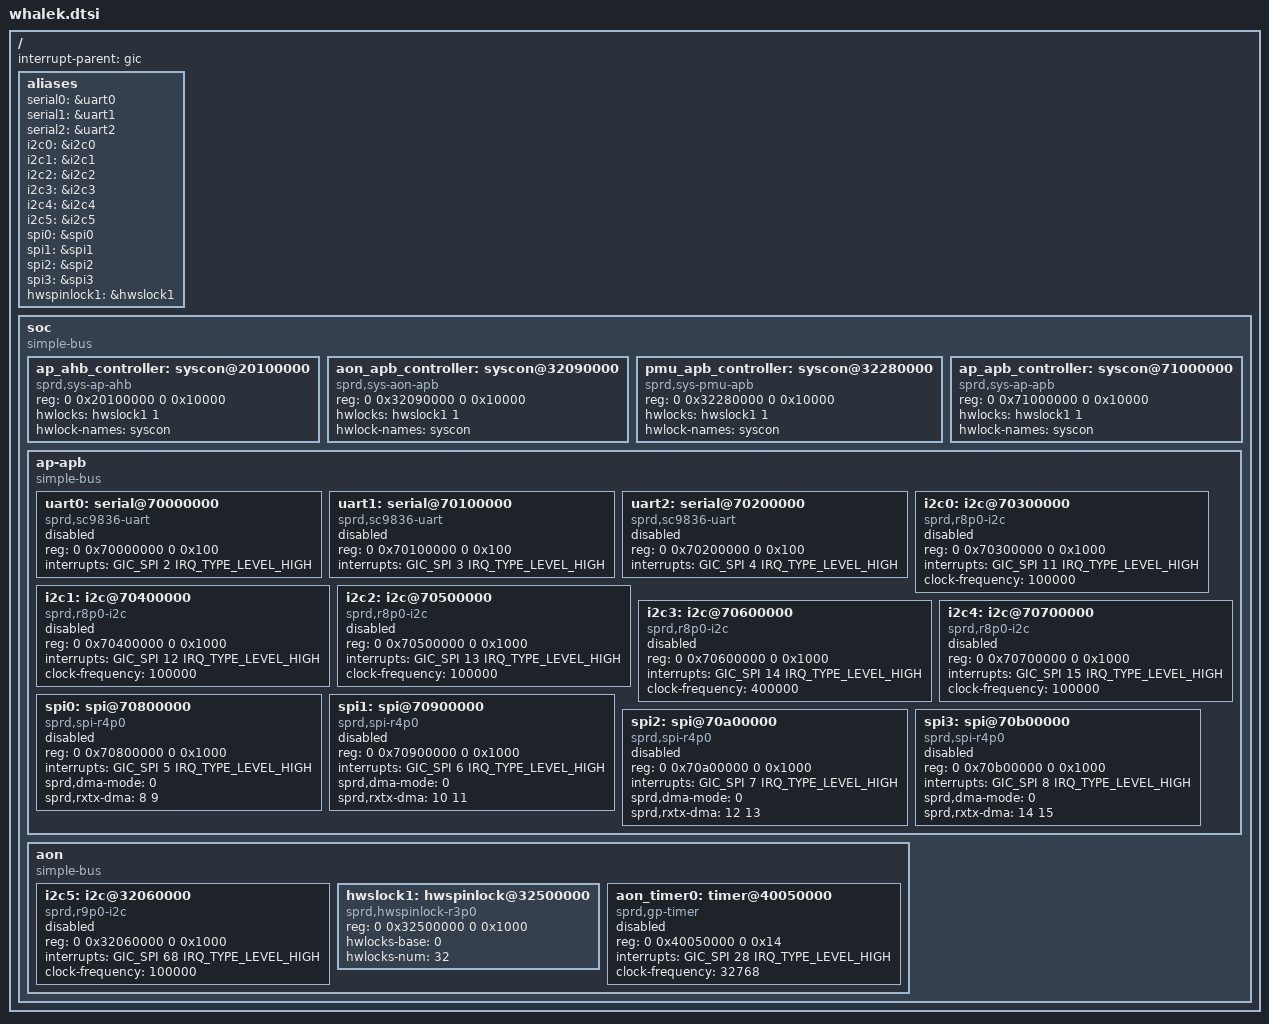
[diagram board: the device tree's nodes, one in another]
/*
 * Spreadtrum Whalek platform DTS file
 *
 * Copyright (C) 2016, Spreadtrum Communications Inc.
 *
 * This file is licensed under a dual GPLv2 or X11 license.
 */

#include <dt-bindings/interrupt-controller/arm-gic.h>

/ {
	interrupt-parent = <&gic>;
	#address-cells = <2>;
	#size-cells = <2>;

	aliases {
		serial0 = &uart0;
		serial1 = &uart1;
		serial2 = &uart2;
		i2c0 = &i2c0;
		i2c1 = &i2c1;
		i2c2 = &i2c2;
		i2c3 = &i2c3;
		i2c4 = &i2c4;
		i2c5 = &i2c5;
		spi0 = &spi0;
		spi1 = &spi1;
		spi2 = &spi2;
		spi3 = &spi3;
		hwspinlock1 = &hwslock1;
	};
	soc: soc {
		compatible = "simple-bus";
		#address-cells = <2>;
		#size-cells = <2>;
		ranges;

		ap_ahb_controller: syscon@20100000 {
			compatible = "sprd,sys-ap-ahb", "syscon";
			reg = <0 0x20100000 0 0x10000>;
			hwlocks = <&hwslock1 1>;
			hwlock-names = "syscon";
		};

		aon_apb_controller: syscon@32090000 {
			compatible = "sprd,sys-aon-apb", "syscon";
			reg = <0 0x32090000 0 0x10000>;
			hwlocks = <&hwslock1 1>;
			hwlock-names = "syscon";
		};

		pmu_apb_controller: syscon@32280000 {
			compatible = "sprd,sys-pmu-apb", "syscon";
			reg = <0 0x32280000 0 0x10000>;
			hwlocks = <&hwslock1 1>;
			hwlock-names = "syscon";
		};

		ap_apb_controller: syscon@71000000 {
			compatible = "sprd,sys-ap-apb", "syscon";
			reg = <0 0x71000000 0 0x10000>;
			hwlocks = <&hwslock1 1>;
			hwlock-names = "syscon";
		};

		ap-apb {
			compatible = "simple-bus";
			#address-cells = <2>;
			#size-cells = <2>;
			ranges;

			uart0: serial@70000000 {
				compatible = "sprd,sc9836-uart",
					     "sprd,sc9838-uart";
				reg = <0 0x70000000 0 0x100>;
				interrupts = <GIC_SPI 2 IRQ_TYPE_LEVEL_HIGH>;
				clock-names = "enable","uart", "source";
				status = "disabled";
			};

			uart1: serial@70100000 {
				compatible = "sprd,sc9836-uart",
					     "sprd,sc9838-uart";
				reg = <0 0x70100000 0 0x100>;
				interrupts = <GIC_SPI 3 IRQ_TYPE_LEVEL_HIGH>;
				clock-names = "enable","uart", "source";
				status = "disabled";
			};

			uart2: serial@70200000 {
				compatible = "sprd,sc9836-uart",
					     "sprd,sc9838-uart";
				reg = <0 0x70200000 0 0x100>;
				interrupts = <GIC_SPI 4 IRQ_TYPE_LEVEL_HIGH>;
				clock-names = "enable","uart", "source";
				status = "disabled";
			};

			i2c0: i2c@70300000 {
				compatible = "sprd,r8p0-i2c";
				reg = <0 0x70300000 0 0x1000>;
				interrupts = <GIC_SPI 11 IRQ_TYPE_LEVEL_HIGH>;
				clock-names = "enable","i2c", "source";
				clock-frequency = <100000>;
				#address-cells = <1>;
				#size-cells = <0>;
				status = "disabled";
			};

			i2c1: i2c@70400000 {
				compatible = "sprd,r8p0-i2c";
				reg = <0 0x70400000 0 0x1000>;
				interrupts = <GIC_SPI 12 IRQ_TYPE_LEVEL_HIGH>;
				clock-names = "enable","i2c", "source";
				clock-frequency = <100000>;
				#address-cells = <1>;
				#size-cells = <0>;
				status = "disabled";
			};

			i2c2: i2c@70500000 {
				compatible = "sprd,r8p0-i2c";
				reg = <0 0x70500000 0 0x1000>;
				interrupts = <GIC_SPI 13 IRQ_TYPE_LEVEL_HIGH>;
				clock-names = "enable","i2c", "source";
				clock-frequency = <100000>;
				#address-cells = <1>;
				#size-cells = <0>;
				status = "disabled";
			};

			i2c3: i2c@70600000 {
				compatible = "sprd,r8p0-i2c";
				reg = <0 0x70600000 0 0x1000>;
				interrupts = <GIC_SPI 14 IRQ_TYPE_LEVEL_HIGH>;
				clock-names = "enable","i2c", "source";
				clock-frequency = <400000>;
				#address-cells = <1>;
				#size-cells = <0>;
				status = "disabled";
			};

			i2c4: i2c@70700000 {
				compatible = "sprd,r8p0-i2c";
				reg = <0 0x70700000 0 0x1000>;
				interrupts = <GIC_SPI 15 IRQ_TYPE_LEVEL_HIGH>;
				clock-names = "enable","i2c", "source";
				clock-frequency = <100000>;
				#address-cells = <1>;
				#size-cells = <0>;
				status = "disabled";
			};

			spi0: spi@70800000{
				compatible = "sprd,spi-r4p0";
				reg = <0 0x70800000 0 0x1000>;
				interrupts = <GIC_SPI 5 IRQ_TYPE_LEVEL_HIGH>;
				clock-names = "enable", "spi", "source";
				sprd,dma-mode = <0>;
				sprd,rxtx-dma = <8 9>;
				dma-names = "rx_chn", "tx_chn";
				#address-cells = <1>;
				#size-cells = <0>;
				status = "disabled";
			};

			spi1: spi@70900000{
				compatible = "sprd,spi-r4p0";
				reg = <0 0x70900000 0 0x1000>;
				interrupts = <GIC_SPI 6 IRQ_TYPE_LEVEL_HIGH>;
				clock-names = "enable", "spi", "source";
				sprd,dma-mode = <0>;
				sprd,rxtx-dma = <10 11>;
				dma-names = "rx_chn", "tx_chn";
				#address-cells = <1>;
				#size-cells = <0>;
				status = "disabled";
			};

			spi2: spi@70a00000{
				compatible = "sprd,spi-r4p0";
				reg = <0 0x70a00000 0 0x1000>;
				interrupts = <GIC_SPI 7 IRQ_TYPE_LEVEL_HIGH>;
				clock-names = "enable", "spi", "source";
				sprd,dma-mode = <0>;
				sprd,rxtx-dma = <12 13>;
				dma-names = "rx_chn", "tx_chn";
				#address-cells = <1>;
				#size-cells = <0>;
				status = "disabled";
			};

			spi3: spi@70b00000{
				compatible = "sprd,spi-r4p0";
				reg = <0 0x70b00000 0 0x1000>;
				interrupts = <GIC_SPI 8 IRQ_TYPE_LEVEL_HIGH>;
				clock-names = "enable", "spi", "source";
				sprd,dma-mode = <0>;
				sprd,rxtx-dma = <14 15>;
				dma-names = "rx_chn", "tx_chn";
				#address-cells = <1>;
				#size-cells = <0>;
				status = "disabled";
			};
		};

		aon {
			compatible = "simple-bus";
			#address-cells = <2>;
			#size-cells = <2>;
			ranges;

			i2c5: i2c@32060000 {
				compatible = "sprd,r9p0-i2c";
				reg = <0 0x32060000 0 0x1000>;
				interrupts = <GIC_SPI 68 IRQ_TYPE_LEVEL_HIGH>;
				clock-names = "enable","i2c", "source",
					"clk_hw_i2c";
				clock-frequency = <100000>;
				#address-cells = <1>;
				#size-cells = <0>;
				status = "disabled";
			};

			hwslock1: hwspinlock@32500000{
				compatible  = "sprd,hwspinlock-r3p0";
				reg = <0 0x32500000 0 0x1000>;
				#hwlock-cells = <1>;
				hwlocks-base = <0>;
				hwlocks-num = <32>;
			};

			aon_timer0: timer@40050000 {
				compatible = "sprd,gp-timer";
				reg = <0 0x40050000 0 0x14>;
				interrupts = <GIC_SPI 28 IRQ_TYPE_LEVEL_HIGH>;
				clock-frequency = <32768>;
				status = "disable";
			};
		};

	};
};

